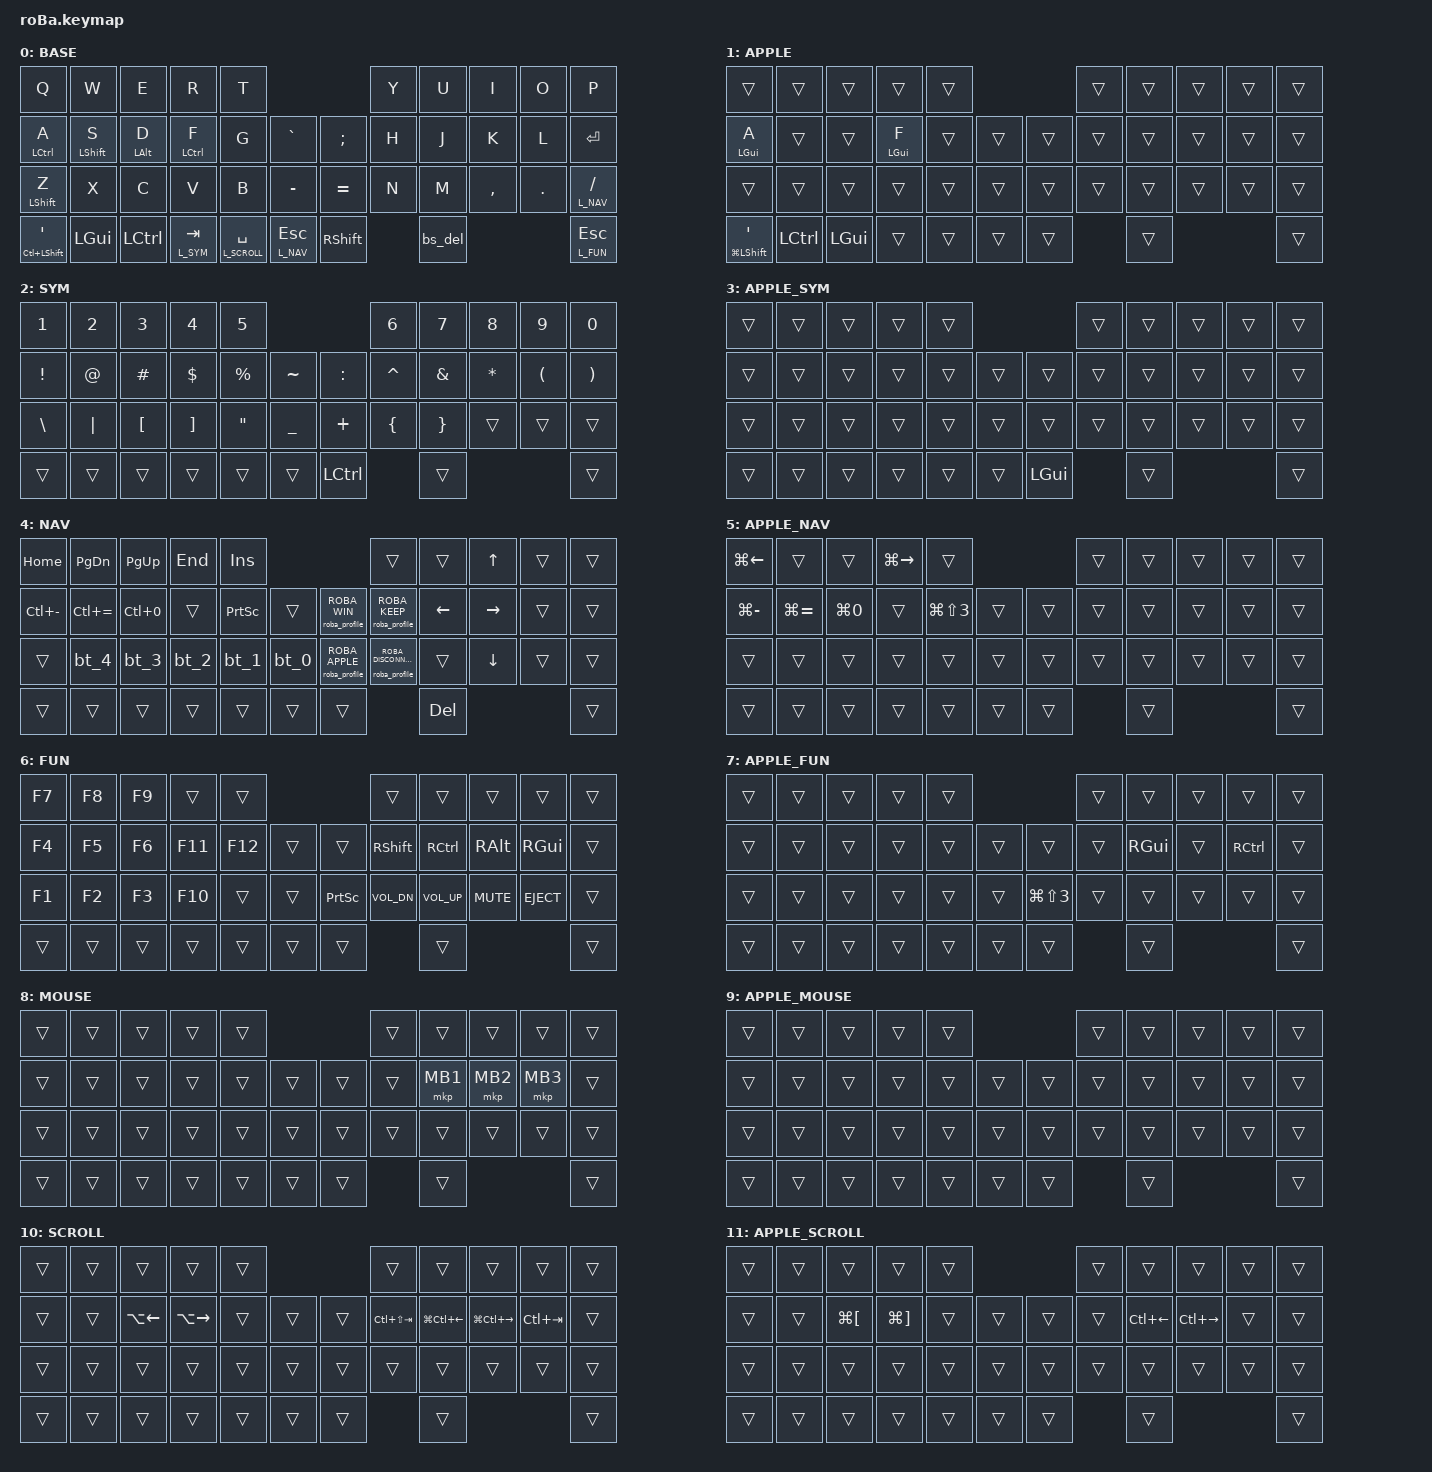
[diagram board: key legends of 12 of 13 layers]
#include <behaviors.dtsi>
#include <dt-bindings/zmk/bt.h>
#include <dt-bindings/zmk/keys.h>
#include <dt-bindings/zmk/pointing.h>

// Keep each Apple override just above its shared layer so layer priority is unchanged.
#define L_BASE 0
#define L_APPLE 1
#define L_SYM 2
#define L_APPLE_SYM 3
#define L_NAV 4
#define L_APPLE_NAV 5
#define L_FUN 6
#define L_APPLE_FUN 7
#define L_MOUSE 8
#define L_APPLE_MOUSE 9
#define L_SCROLL 10
#define L_APPLE_SCROLL 11
#define L_CONFIG 12

#define ROBA_WIN 0
#define ROBA_APPLE 1
#define ROBA_KEEP 2
#define ROBA_DISCONNECT 3

&lt {
    tapping-term-ms = <200>;
    quick-tap-ms = <175>;
};

&trackball {
    automouse-layer = <L_MOUSE>;
    // The PMW3610 driver checks the highest active layer, including Apple overrides.
    scroll-layers = <L_SCROLL L_APPLE_SCROLL>;
};

/ {
    macros {
        // Profile policy is applied by the central-side profile-settings behavior.
        bt_0: bt_0 {
            compatible = "zmk,behavior-macro";
            #binding-cells = <0>;
            wait-ms = <0>;
            tap-ms = <0>;
            bindings = <&bt BT_SEL 0>;
        };

        bt_1: bt_1 {
            compatible = "zmk,behavior-macro";
            #binding-cells = <0>;
            wait-ms = <0>;
            tap-ms = <0>;
            bindings = <&bt BT_SEL 1>;
        };

        bt_2: bt_2 {
            compatible = "zmk,behavior-macro";
            #binding-cells = <0>;
            wait-ms = <0>;
            tap-ms = <0>;
            bindings = <&bt BT_SEL 2>;
        };

        bt_3: bt_3 {
            compatible = "zmk,behavior-macro";
            #binding-cells = <0>;
            wait-ms = <0>;
            tap-ms = <0>;
            bindings = <&bt BT_SEL 3>;
        };

        bt_4: bt_4 {
            compatible = "zmk,behavior-macro";
            #binding-cells = <0>;
            wait-ms = <0>;
            tap-ms = <0>;
            bindings = <&bt BT_SEL 4>;
        };

        release_mods: release_mods {
            compatible = "zmk,behavior-macro";
            #binding-cells = <0>;
            bindings = <&macro_release &kp LSHFT &kp LCTRL &kp LALT &kp LGUI &kp RSHFT &kp RCTRL &kp RALT &kp RGUI>;
        };
    };

    behaviors {
        roba_profile: roba_profile {
            compatible = "zmk,behavior-profile-settings";
            #binding-cells = <1>;
            apple-layer = <L_APPLE>;
            base-layer = <L_BASE>;
        };

        hm: home_row_mod {
            compatible = "zmk,behavior-hold-tap";
            #binding-cells = <2>;
            flavor = "tap-preferred";
            tapping-term-ms = <280>;
            quick-tap-ms = <175>;
            require-prior-idle-ms = <250>;
            bindings = <&kp>, <&kp>;
        };

        bs_del: backspace_delete {
            compatible = "zmk,behavior-mod-morph";
            #binding-cells = <0>;
            bindings = <&kp BACKSPACE>, <&kp DELETE>;
            mods = <(MOD_LSFT|MOD_RSFT)>;
        };

        scroll_encoder: scroll_encoder {
            compatible = "zmk,behavior-sensor-rotate";
            #sensor-binding-cells = <0>;
            bindings = <&msc SCRL_RIGHT>, <&msc SCRL_LEFT>;
        };
    };

    combos {
        compatible = "zmk,combos";

        esc {
            bindings = <&kp ESC>;
            key-positions = <11 12>;
            timeout-ms = <50>;
            require-prior-idle-ms = <150>;
            layers = <L_BASE L_APPLE>;
        };

        kana {
            bindings = <&kp LANG1>;
            key-positions = <12 13>;
            timeout-ms = <50>;
            require-prior-idle-ms = <150>;
            layers = <L_BASE L_APPLE>;
        };

        eisu {
            bindings = <&kp LANG2>;
            key-positions = <18 19>;
            timeout-ms = <50>;
            require-prior-idle-ms = <150>;
            layers = <L_BASE L_APPLE>;
        };

        unstuck {
            bindings = <&release_mods>;
            key-positions = <34 42>;
            timeout-ms = <50>;
        };
    };

    conditional_layers {
        compatible = "zmk,conditional-layers";

        config_layer {
            // Hold the left-thumb Tab (SYM) and right-thumb Esc (FUN) keys.
            if-layers = <L_SYM L_FUN>;
            then-layer = <L_CONFIG>;
        };

        apple_sym {
            if-layers = <L_APPLE L_SYM>;
            then-layer = <L_APPLE_SYM>;
        };

        apple_nav {
            if-layers = <L_APPLE L_NAV>;
            then-layer = <L_APPLE_NAV>;
        };

        apple_fun {
            if-layers = <L_APPLE L_FUN>;
            then-layer = <L_APPLE_FUN>;
        };

        apple_mouse {
            if-layers = <L_APPLE L_MOUSE>;
            then-layer = <L_APPLE_MOUSE>;
        };

        apple_scroll {
            if-layers = <L_APPLE L_SCROLL>;
            then-layer = <L_APPLE_SCROLL>;
        };
    };

    keymap {
        compatible = "zmk,keymap";

        BASE {
            bindings = <
&kp Q        &kp W       &kp E      &kp R        &kp T                                          &kp Y      &kp U  &kp I      &kp O    &kp P
&hm LCTRL A  &hm LSHFT S &hm LALT D &hm LCTRL F  &kp G        &kp GRAVE        &kp SEMI        &kp H      &kp J  &kp K      &kp L    &kp ENTER
&hm LSHFT Z  &kp X      &kp C       &kp V        &kp B        &kp MINUS        &kp EQUAL       &kp N      &kp M  &kp COMMA  &kp DOT  &lt L_NAV FSLH
&hm LC(LSHFT) SQT &kp LGUI &kp LCTRL &lt L_SYM TAB &lt L_SCROLL SPACE &lt L_NAV ESC &kp RSHFT            &bs_del                    &lt L_FUN ESC
            >;

            sensor-bindings = <&inc_dec_kp DOWN UP>;
        };

        APPLE {
            bindings = <
&trans       &trans     &trans  &trans       &trans                    &trans  &trans  &trans  &trans  &trans
&hm LGUI A   &trans     &trans  &hm LGUI F   &trans  &trans    &trans  &trans  &trans  &trans  &trans  &trans
&trans       &trans     &trans  &trans       &trans  &trans    &trans  &trans  &trans  &trans  &trans  &trans
&hm LG(LSHFT) SQT &kp LCTRL &kp LGUI &trans  &trans  &trans    &trans  &trans                          &trans
            >;
        };

        SYM {
            bindings = <
&kp N1    &kp N2    &kp N3    &kp N4    &kp N5                                     &kp N6     &kp N7     &kp N8     &kp N9    &kp N0
&kp EXCL  &kp AT    &kp HASH  &kp DLLR  &kp PRCNT  &kp TILDE        &kp COLON     &kp CARET  &kp AMPS   &kp ASTRK  &kp LPAR  &kp RPAR
&kp BSLH  &kp PIPE  &kp LBKT  &kp RBKT  &kp DQT    &kp UNDER        &kp PLUS      &kp LBRC   &kp RBRC   &trans     &trans    &trans
&trans    &trans    &trans    &trans    &trans     &trans           &kp LCTRL     &trans                                     &trans
            >;

            sensor-bindings = <&inc_dec_kp C_VOL_UP C_VOL_DN>;
        };

        APPLE_SYM {
            bindings = <
&trans  &trans  &trans  &trans  &trans                    &trans  &trans  &trans  &trans  &trans
&trans  &trans  &trans  &trans  &trans  &trans    &trans  &trans  &trans  &trans  &trans  &trans
&trans  &trans  &trans  &trans  &trans  &trans    &trans  &trans  &trans  &trans  &trans  &trans
&trans  &trans  &trans  &trans  &trans  &trans    &kp LGUI &trans                         &trans
            >;
        };

        NAV {
            bindings = <
&kp HOME       &kp PG_DN      &kp PG_UP   &kp END  &kp INS                                   &trans    &trans     &kp UP     &trans     &trans
&kp LC(MINUS)  &kp LC(EQUAL)  &kp LC(N0)  &trans   &kp PSCRN  &trans          &roba_profile ROBA_WIN  &roba_profile ROBA_KEEP  &kp LEFT   &kp RIGHT  &trans     &trans
&trans  &bt_4         &bt_3         &bt_2         &bt_1         &bt_0                 &roba_profile ROBA_APPLE  &roba_profile ROBA_DISCONNECT  &trans     &kp DOWN   &trans     &trans
&trans         &trans         &trans      &trans   &trans     &trans          &trans         &kp DEL                                   &trans
            >;

            sensor-bindings = <&inc_dec_kp LC(PG_DN) LC(PG_UP)>;
        };

        APPLE_NAV {
            bindings = <
&kp LG(LEFT)  &trans        &trans     &kp LG(RIGHT) &trans                       &trans  &trans  &trans  &trans  &trans
&kp LG(MINUS) &kp LG(EQUAL) &kp LG(N0) &trans        &kp LG(LS(N3)) &trans &trans  &trans  &trans  &trans  &trans  &trans
&trans        &trans        &trans     &trans        &trans         &trans &trans  &trans  &trans  &trans  &trans  &trans
&trans        &trans        &trans     &trans        &trans         &trans &trans  &trans                          &trans
            >;

            sensor-bindings = <&inc_dec_kp LC(TAB) LC(LS(TAB))>;
        };

        FUN {
            bindings = <
&kp F7  &kp F8  &kp F9  &trans   &trans                                       &trans        &trans        &trans        &trans      &trans
&kp F4  &kp F5  &kp F6  &kp F11  &kp F12  &trans          &trans              &kp RSHFT     &kp RCTRL     &kp RALT      &kp RGUI    &trans
&kp F1  &kp F2  &kp F3  &kp F10  &trans   &trans          &kp PSCRN           &kp C_VOL_DN  &kp C_VOL_UP  &kp C_MUTE    &kp C_EJECT      &trans
&trans  &trans  &trans  &trans   &trans   &trans          &trans              &trans                                                 &trans
            >;

            sensor-bindings = <&inc_dec_kp LA(RIGHT) LA(LEFT)>;
        };

        APPLE_FUN {
            bindings = <
&trans  &trans  &trans  &trans  &trans                          &trans  &trans   &trans  &trans    &trans
&trans  &trans  &trans  &trans  &trans  &trans    &trans        &trans  &kp RGUI &trans  &kp RCTRL &trans
&trans  &trans  &trans  &trans  &trans  &trans    &kp LG(LS(N3)) &trans  &trans   &trans  &trans    &trans
&trans  &trans  &trans  &trans  &trans  &trans    &trans        &trans                            &trans
            >;

            sensor-bindings = <&inc_dec_kp LG(RBKT) LG(LBKT)>;
        };

        MOUSE {
            bindings = <
&trans  &trans  &trans  &trans  &trans                      &trans  &trans    &trans    &trans    &trans
&trans  &trans  &trans  &trans  &trans  &trans      &trans  &trans  &mkp MB1  &mkp MB2  &mkp MB3  &trans
&trans  &trans  &trans  &trans  &trans  &trans      &trans  &trans  &trans    &trans    &trans    &trans
&trans  &trans  &trans  &trans  &trans  &trans      &trans  &trans                                &trans
            >;

            sensor-bindings = <&inc_dec_kp LC(EQUAL) LC(MINUS)>;
        };

        APPLE_MOUSE {
            bindings = <
&trans  &trans  &trans  &trans  &trans                    &trans  &trans  &trans  &trans  &trans
&trans  &trans  &trans  &trans  &trans  &trans    &trans  &trans  &trans  &trans  &trans  &trans
&trans  &trans  &trans  &trans  &trans  &trans    &trans  &trans  &trans  &trans  &trans  &trans
&trans  &trans  &trans  &trans  &trans  &trans    &trans  &trans                          &trans
            >;

            sensor-bindings = <&inc_dec_kp LG(EQUAL) LG(MINUS)>;
        };

        SCROLL {
            bindings = <
&trans  &trans  &trans        &trans         &trans                          &trans        &trans        &trans        &trans        &trans
&trans  &trans  &kp LA(LEFT)  &kp LA(RIGHT)  &trans  &trans      &trans      &kp LC(LS(TAB))  &kp LG(LC(LEFT))  &kp LG(LC(RIGHT))  &kp LC(TAB)   &trans
&trans  &trans  &trans        &trans         &trans  &trans      &trans      &trans           &trans            &trans             &trans        &trans
&trans  &trans  &trans        &trans         &trans  &trans      &trans      &trans                                                              &trans
            >;

            sensor-bindings = <&scroll_encoder>;
        };

        APPLE_SCROLL {
            bindings = <
&trans  &trans  &trans       &trans       &trans                    &trans  &trans       &trans        &trans  &trans
&trans  &trans  &kp LG(LBKT) &kp LG(RBKT) &trans  &trans    &trans  &trans  &kp LC(LEFT) &kp LC(RIGHT) &trans  &trans
&trans  &trans  &trans       &trans       &trans  &trans    &trans  &trans  &trans       &trans        &trans  &trans
&trans  &trans  &trans       &trans       &trans  &trans    &trans  &trans                                           &trans
            >;
        };

        CONFIG {
            bindings = <
&trans      &roba_profile ROBA_WIN &trans  &trans  &trans                 &bt_0         &bt_1         &bt_2         &bt_3         &bt_4
&roba_profile ROBA_APPLE &trans    &trans  &trans  &trans  &trans    &trans         &trans        &trans        &trans        &trans        &bt BT_CLR
&trans  &trans  &trans  &trans  &trans  &bootloader     &trans         &trans        &trans        &trans        &trans        &bt BT_CLR_ALL
&trans  &trans  &trans  &trans  &trans  &trans          &trans         &trans                                                  &trans
            >;
        };
    };
};
